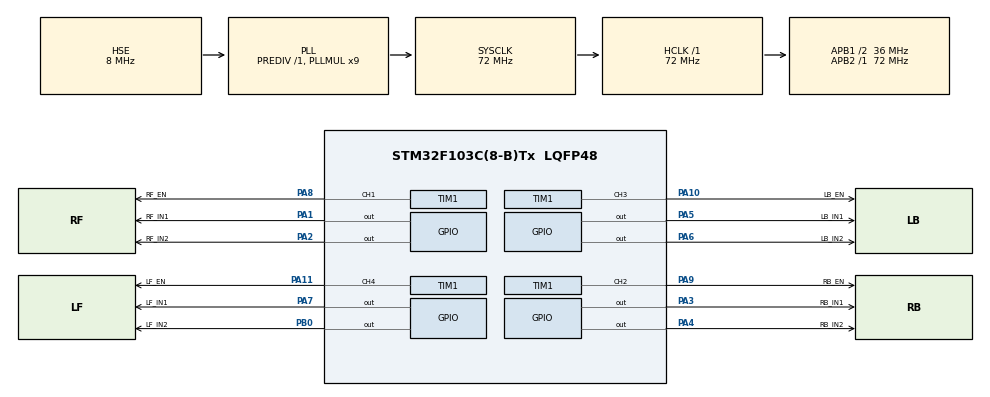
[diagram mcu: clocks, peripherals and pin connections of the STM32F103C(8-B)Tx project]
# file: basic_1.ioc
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Mcu.Family=STM32F1
Mcu.Name=STM32F103C(8-B)Tx
Mcu.Package=LQFP48
NVIC.PriorityGroup=NVIC_PRIORITYGROUP_4
PA1.GPIO_Label=RF_IN1
PA1.GPIO_PuPd=GPIO_NOPULL
PA1.Signal=GPIO_Output
PA10.GPIO_Label=LB_EN
PA10.Signal=S_TIM1_CH3
PA11.GPIO_Label=LF_EN
PA11.Signal=S_TIM1_CH4
PA13.Mode=Serial_Wire
PA13.Signal=SYS_JTMS-SWDIO
PA14.Mode=Serial_Wire
PA14.Signal=SYS_JTCK-SWCLK
PA2.GPIO_Label=RF_IN2
PA2.Signal=GPIO_Output
PA3.GPIO_Label=RB_IN1
PA3.Signal=GPIO_Output
PA4.GPIO_Label=RB_IN2
PA4.Signal=GPIO_Output
PA5.GPIO_Label=LB_IN1
PA5.Signal=GPIO_Output
PA6.GPIO_Label=LB_IN2
PA6.Signal=GPIO_Output
PA7.GPIO_Label=LF_IN1
PA7.Signal=GPIO_Output
PA8.GPIO_Label=RF_EN
PA8.Signal=S_TIM1_CH1
PA9.GPIO_Label=RB_EN
PA9.Signal=S_TIM1_CH2
PB0.GPIO_Label=LF_IN2
PB0.Signal=GPIO_Output
PD0-OSC_IN.Mode=HSE-External-Oscillator
PD0-OSC_IN.Signal=RCC_OSC_IN
PD1-OSC_OUT.Mode=HSE-External-Oscillator
PD1-OSC_OUT.Signal=RCC_OSC_OUT
ProjectManager.HeapSize=0x200
ProjectManager.StackSize=0x400
ProjectManager.TargetToolchain=STM32CubeIDE
RCC.AHBFreq_Value=72000000
RCC.APB1CLKDivider=RCC_HCLK_DIV2
RCC.APB1Freq_Value=36000000
RCC.APB1TimFreq_Value=72000000
RCC.APB2Freq_Value=72000000
RCC.APB2TimFreq_Value=72000000
RCC.HCLKFreq_Value=72000000
RCC.PLLMUL=RCC_PLL_MUL9
RCC.PLLSourceVirtual=RCC_PLLSOURCE_HSE
RCC.SYSCLKFreq_VALUE=72000000
RCC.SYSCLKSource=RCC_SYSCLKSOURCE_PLLCLK
RCC.USBFreq_Value=72000000
SH.S_TIM1_CH1.0=TIM1_CH1,Output Compare1 CH1
SH.S_TIM1_CH2.0=TIM1_CH2,Output Compare2 CH2
SH.S_TIM1_CH3.0=TIM1_CH3,Output Compare3 CH3
SH.S_TIM1_CH4.0=TIM1_CH4,Output Compare4 CH4
TIM1.Channel-Output\ Compare1\ CH1=TIM_CHANNEL_1
TIM1.Channel-Output\ Compare2\ CH2=TIM_CHANNEL_2
TIM1.Channel-Output\ Compare3\ CH3=TIM_CHANNEL_3
TIM1.Channel-Output\ Compare4\ CH4=TIM_CHANNEL_4
TIM1.OCMode_1=TIM_OCMODE_TOGGLE
TIM1.OCMode_2=TIM_OCMODE_TOGGLE
TIM1.OCMode_3=TIM_OCMODE_TOGGLE
TIM1.OCMode_4=TIM_OCMODE_TOGGLE
TIM1.Period=100 - 1
TIM1.Prescaler=72 - 1
TIM1.Pulse-Output\ Compare2\ CH2=50
TIM1.Pulse-Output\ Compare3\ CH3=50
TIM1.Pulse-Output\ Compare4\ CH4=50
VP_TIM1_VS_ClockSourceINT.Mode=Internal
board=custom

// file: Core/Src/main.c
/* USER CODE BEGIN Header */
/**
  ******************************************************************************
  * @file           : main.c
  * @brief          : Main program body
  ******************************************************************************
  * @attention
  *
  * Copyright (c) 2025 STMicroelectronics.
  * All rights reserved.
  *
  * This software is licensed under terms that can be found in the LICENSE file
  * in the root directory of this software component.
  * If no LICENSE file comes with this software, it is provided AS-IS.
  *
  ******************************************************************************
  */
/* USER CODE END Header */
#include "main.h"
#include "tim.h"
#include "gpio.h"

/* USER CODE BEGIN Includes */
#include "DriverMotor.h"
/* USER CODE END Includes */

void SystemClock_Config(void);

int main(void)
{

  /* MCU Configuration--------------------------------------------------------*/

  /* Reset of all peripherals, Initializes the Flash interface and the Systick. */
  HAL_Init();

  /* Configure the system clock */
  SystemClock_Config();

  /* Initialize all configured peripherals */
  MX_GPIO_Init();
  MX_TIM1_Init();

  /* Infinite loop */
  /* USER CODE BEGIN WHILE */
  while (1)
  {
    car_go_forward(1);
    HAL_Delay(1000);
    car_go_back(1);
    HAL_Delay(1000);
    car_stop();
    HAL_Delay(1000);
    /* USER CODE END WHILE */

  }
}

void SystemClock_Config(void)
{
  RCC_OscInitTypeDef RCC_OscInitStruct = {0};
  RCC_ClkInitTypeDef RCC_ClkInitStruct = {0};

  /** Initializes the RCC Oscillators according to the specified parameters
  * in the RCC_OscInitTypeDef structure.
  */
  RCC_OscInitStruct.OscillatorType = RCC_OSCILLATORTYPE_HSE;
  RCC_OscInitStruct.HSEState = RCC_HSE_ON;
  RCC_OscInitStruct.HSEPredivValue = RCC_HSE_PREDIV_DIV1;
  RCC_OscInitStruct.HSIState = RCC_HSI_ON;
  RCC_OscInitStruct.PLL.PLLState = RCC_PLL_ON;
  RCC_OscInitStruct.PLL.PLLSource = RCC_PLLSOURCE_HSE;
  RCC_OscInitStruct.PLL.PLLMUL = RCC_PLL_MUL9;
  if (HAL_RCC_OscConfig(&RCC_OscInitStruct) != HAL_OK)
  {
    Error_Handler();
  }

  /** Initializes the CPU, AHB and APB buses clocks
  */
  RCC_ClkInitStruct.ClockType = RCC_CLOCKTYPE_HCLK|RCC_CLOCKTYPE_SYSCLK
                              |RCC_CLOCKTYPE_PCLK1|RCC_CLOCKTYPE_PCLK2;
  RCC_ClkInitStruct.SYSCLKSource = RCC_SYSCLKSOURCE_PLLCLK;
  RCC_ClkInitStruct.AHBCLKDivider = RCC_SYSCLK_DIV1;
  RCC_ClkInitStruct.APB1CLKDivider = RCC_HCLK_DIV2;
  RCC_ClkInitStruct.APB2CLKDivider = RCC_HCLK_DIV1;

  if (HAL_RCC_ClockConfig(&RCC_ClkInitStruct, FLASH_LATENCY_2) != HAL_OK)
  {
    Error_Handler();
  }
}

void Error_Handler(void)
{
  __disable_irq();
  while (1)
  {
  }
}
